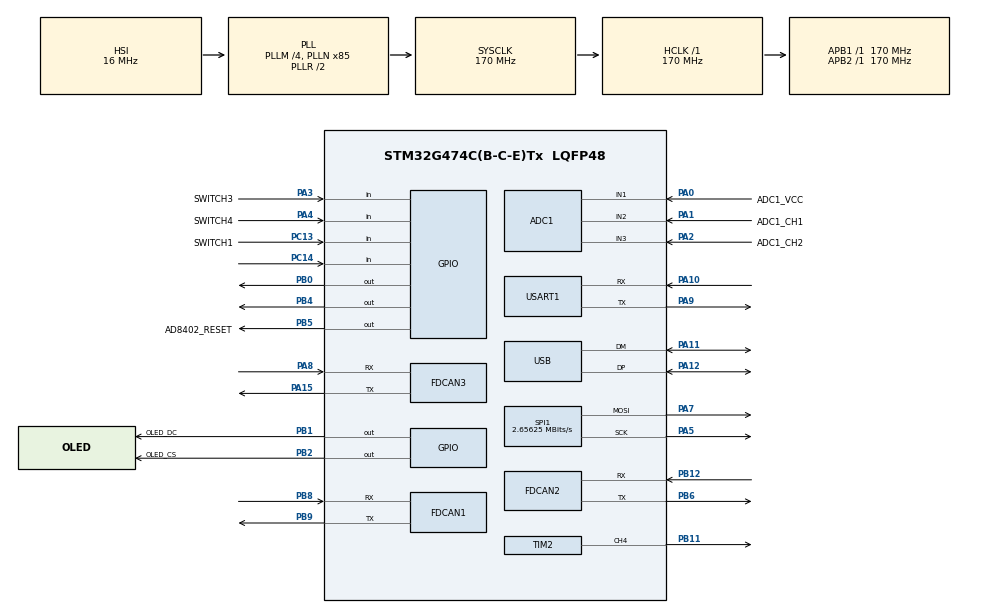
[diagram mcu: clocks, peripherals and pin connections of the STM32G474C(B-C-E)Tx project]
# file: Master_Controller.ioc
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ADC1.Channel-0\#ChannelRegularConversion=ADC_CHANNEL_VREFINT
ADC1.NbrOfConversionFlag=1
ADC1.OffsetNumber-0\#ChannelRegularConversion=ADC_OFFSET_NONE
ADC1.Rank-0\#ChannelRegularConversion=1
ADC1.SamplingTime-0\#ChannelRegularConversion=ADC_SAMPLETIME_2CYCLES_5
ADC1.master=1
Dma.Request0=USART1_RX
Dma.Request1=TIM2_CH4
Dma.TIM2_CH4.1.Direction=DMA_MEMORY_TO_PERIPH
Dma.TIM2_CH4.1.EventEnable=DISABLE
Dma.TIM2_CH4.1.Instance=DMA1_Channel2
Dma.TIM2_CH4.1.MemDataAlignment=DMA_MDATAALIGN_WORD
Dma.TIM2_CH4.1.MemInc=DMA_MINC_ENABLE
Dma.TIM2_CH4.1.Mode=DMA_CIRCULAR
Dma.TIM2_CH4.1.PeriphDataAlignment=DMA_PDATAALIGN_WORD
Dma.TIM2_CH4.1.PeriphInc=DMA_PINC_DISABLE
Dma.TIM2_CH4.1.Polarity=HAL_DMAMUX_REQ_GEN_RISING
Dma.TIM2_CH4.1.Priority=DMA_PRIORITY_LOW
Dma.TIM2_CH4.1.RequestNumber=1
Dma.TIM2_CH4.1.SignalID=NONE
Dma.TIM2_CH4.1.SyncEnable=DISABLE
Dma.TIM2_CH4.1.SyncPolarity=HAL_DMAMUX_SYNC_NO_EVENT
Dma.TIM2_CH4.1.SyncRequestNumber=1
Dma.TIM2_CH4.1.SyncSignalID=NONE
Dma.USART1_RX.0.Direction=DMA_PERIPH_TO_MEMORY
Dma.USART1_RX.0.EventEnable=DISABLE
Dma.USART1_RX.0.Instance=DMA1_Channel1
Dma.USART1_RX.0.MemDataAlignment=DMA_MDATAALIGN_BYTE
Dma.USART1_RX.0.MemInc=DMA_MINC_ENABLE
Dma.USART1_RX.0.Mode=DMA_NORMAL
Dma.USART1_RX.0.PeriphDataAlignment=DMA_PDATAALIGN_BYTE
Dma.USART1_RX.0.PeriphInc=DMA_PINC_DISABLE
Dma.USART1_RX.0.Polarity=HAL_DMAMUX_REQ_GEN_RISING
Dma.USART1_RX.0.Priority=DMA_PRIORITY_LOW
Dma.USART1_RX.0.RequestNumber=1
Dma.USART1_RX.0.SignalID=NONE
Dma.USART1_RX.0.SyncEnable=DISABLE
Dma.USART1_RX.0.SyncPolarity=HAL_DMAMUX_SYNC_NO_EVENT
Dma.USART1_RX.0.SyncRequestNumber=1
Dma.USART1_RX.0.SyncSignalID=NONE
FDCAN1.AutoRetransmission=ENABLE
FDCAN1.CalculateBaudRateNominal=1700000
FDCAN1.CalculateTimeBitNominal=588
FDCAN1.CalculateTimeQuantumNominal=58.82352941176471
FDCAN1.DataPrescaler=17
FDCAN1.DataTimeSeg1=6
FDCAN1.DataTimeSeg2=3
FDCAN1.ExtFiltersNbr=8
FDCAN1.NominalPrescaler=10
FDCAN1.NominalTimeSeg1=6
FDCAN1.NominalTimeSeg2=3
FDCAN1.ProtocolException=ENABLE
FDCAN1.StdFiltersNbr=8
FDCAN1.TransmitPause=ENABLE
FDCAN2.AutoRetransmission=ENABLE
FDCAN2.CalculateBaudRateNominal=1700000
FDCAN2.CalculateTimeBitNominal=588
FDCAN2.CalculateTimeQuantumNominal=58.82352941176471
FDCAN2.DataPrescaler=17
FDCAN2.DataSyncJumpWidth=1
FDCAN2.DataTimeSeg1=6
FDCAN2.DataTimeSeg2=3
FDCAN2.ExtFiltersNbr=8
FDCAN2.NominalPrescaler=10
FDCAN2.NominalTimeSeg1=6
FDCAN2.NominalTimeSeg2=3
FDCAN2.ProtocolException=ENABLE
FDCAN2.StdFiltersNbr=8
FDCAN2.TransmitPause=ENABLE
FDCAN3.CalculateBaudRateNominal=3541666
FDCAN3.CalculateTimeBitNominal=282
FDCAN3.CalculateTimeQuantumNominal=94.11764705882354
FREERTOS.Tasks01=defaultTask,24,256,StartDefaultTask,Default,NULL,Dynamic,NULL,NULL;RGB,9,512,Task_RGB,As weak,NULL,Dynamic,NULL,NULL;Communite,49,1024,Task_Communite,As weak,NULL,Dynamic,NULL,NULL;Main_Control,41,2048,Task_Main_Control,As weak,NULL,Dynamic,NULL,NULL;Error_Detect,16,256,Task_Error_Detect,As weak,NULL,Dynamic,NULL,NULL;OLED,8,2048,Task_OLED_Display,As weak,NULL,Dynamic,NULL,NULL
FREERTOS.configTOTAL_HEAP_SIZE=32767
Mcu.Family=STM32G4
Mcu.Name=STM32G474C(B-C-E)Tx
Mcu.Package=LQFP48
NVIC.DMA1_Channel1_IRQn=true\:5\:0\:false\:false\:true\:true\:false\:true\:true
NVIC.DMA1_Channel2_IRQn=true\:5\:0\:false\:false\:true\:true\:false\:true\:true
NVIC.FDCAN1_IT0_IRQn=true\:5\:0\:false\:false\:true\:true\:true\:true\:true
NVIC.FDCAN2_IT0_IRQn=true\:5\:0\:false\:false\:true\:true\:true\:true\:true
NVIC.PriorityGroup=NVIC_PRIORITYGROUP_4
NVIC.TIM1_TRG_COM_TIM17_IRQn=true\:15\:0\:false\:false\:true\:false\:false\:true\:true
NVIC.TIM1_UP_TIM16_IRQn=true\:5\:0\:false\:false\:true\:true\:true\:true\:true
NVIC.TIM2_IRQn=true\:5\:0\:false\:false\:true\:true\:true\:true\:true
NVIC.TimeBase=TIM1_TRG_COM_TIM17_IRQn
NVIC.TimeBaseIP=TIM17
PA0.GPIO_Label=ADC1_VCC
PA0.Mode=IN1-Single-Ended
PA0.Signal=ADC1_IN1
PA1.GPIO_Label=ADC1_CH1
PA1.Mode=IN2-Single-Ended
PA1.Signal=ADC1_IN2
PA10.Mode=Asynchronous
PA10.Signal=USART1_RX
PA11.Mode=Device
PA11.Signal=USB_DM
PA12.Mode=Device
PA12.Signal=USB_DP
PA13.Mode=Serial_Wire
PA13.Signal=SYS_JTMS-SWDIO
PA14.Mode=Serial_Wire
PA14.Signal=SYS_JTCK-SWCLK
PA15.Mode=FDCAN_Activate
PA15.Signal=FDCAN3_TX
PA2.GPIO_Label=ADC1_CH2
PA2.Mode=IN3-Single-Ended
PA2.Signal=ADC1_IN3
PA3.GPIO_Label=SWITCH3
PA3.Signal=GPIO_Input
PA4.GPIO_Label=SWITCH4
PA4.Signal=GPIO_Input
PA5.Mode=TX_Only_Simplex_Unidirect_Master
PA5.Signal=SPI1_SCK
PA7.Mode=TX_Only_Simplex_Unidirect_Master
PA7.Signal=SPI1_MOSI
PA8.Mode=FDCAN_Activate
PA8.Signal=FDCAN3_RX
PA9.Mode=Asynchronous
PA9.Signal=USART1_TX
PB0.GPIO_PuPd=GPIO_PULLUP
PB0.GPIO_Speed=GPIO_SPEED_FREQ_HIGH
PB0.Signal=GPIO_Output
PB1.GPIO_Label=OLED_DC
PB1.GPIO_PuPd=GPIO_PULLUP
PB1.GPIO_Speed=GPIO_SPEED_FREQ_HIGH
PB1.Signal=GPIO_Output
PB11.Signal=S_TIM2_CH4
PB12.Mode=FDCAN_Activate
PB12.Signal=FDCAN2_RX
PB2.GPIO_Label=OLED_CS
PB2.GPIO_PuPd=GPIO_PULLUP
PB2.GPIO_Speed=GPIO_SPEED_FREQ_HIGH
PB2.Signal=GPIO_Output
PB4.Signal=GPIO_Output
PB5.GPIO_Label=AD8402_RESET
PB5.Signal=GPIO_Output
PB6.Mode=FDCAN_Activate
PB6.Signal=FDCAN2_TX
PB8-BOOT0.Mode=FDCAN_Activate
PB8-BOOT0.Signal=FDCAN1_RX
PB9.Mode=FDCAN_Activate
PB9.Signal=FDCAN1_TX
PC13.GPIO_Label=SWITCH1
PC13.Signal=GPIO_Input
PC14-OSC32_IN.Signal=GPIO_Input
PF0-OSC_IN.Mode=HSE-External-Oscillator
PF0-OSC_IN.Signal=RCC_OSC_IN
PF1-OSC_OUT.Mode=HSE-External-Oscillator
PF1-OSC_OUT.Signal=RCC_OSC_OUT
ProjectManager.HeapSize=0x200
ProjectManager.StackSize=0x400
ProjectManager.TargetToolchain=MDK-ARM V5.32
RCC.ADC12Freq_Value=170000000
RCC.ADC345Freq_Value=170000000
RCC.AHBFreq_Value=170000000
RCC.APB1Freq_Value=170000000
RCC.APB1TimFreq_Value=170000000
RCC.APB2Freq_Value=170000000
RCC.APB2TimFreq_Value=170000000
RCC.CK48CLockSelection=RCC_USBCLKSOURCE_HSI48
RCC.CortexFreq_Value=170000000
RCC.EXTERNAL_CLOCK_VALUE=12288000
RCC.HCLKFreq_Value=170000000
RCC.HSE_VALUE=12000000
RCC.HSI48_VALUE=48000000
RCC.HSI_VALUE=16000000
RCC.LSE_VALUE=32768
RCC.PLLM=RCC_PLLM_DIV4
RCC.PLLN=85
RCC.PLLQ=RCC_PLLQ_DIV6
RCC.SYSCLKFreq_VALUE=170000000
RCC.SYSCLKSource=RCC_SYSCLKSOURCE_PLLCLK
RCC.USBFreq_Value=48000000
RCC.VCOOutputFreq_Value=340000000
SH.S_TIM2_CH4.0=TIM2_CH4,PWM Generation4 CH4
SPI1.BaudRatePrescaler=SPI_BAUDRATEPRESCALER_64
SPI1.CalculateBaudRate=2.65625 MBits/s
SPI1.DataSize=SPI_DATASIZE_10BIT
SPI1.Direction=SPI_DIRECTION_2LINES
SPI1.Mode=SPI_MODE_MASTER
SPI1.VirtualType=VM_MASTER
TIM1.PeriodNoDither=1000
TIM1.Prescaler=170
TIM2.AutoReloadPreload=TIM_AUTORELOAD_PRELOAD_ENABLE
TIM2.Channel-PWM\ Generation4\ CH4=TIM_CHANNEL_4
TIM2.ClockDivision=TIM_CLOCKDIVISION_DIV1
TIM2.PeriodNoDither=200-1
TIM2.PulseNoDither_4=0
USART1.VirtualMode-Asynchronous=VM_ASYNC
VP_ADC1_Vref_Input.Mode=IN-Vrefint
VP_FREERTOS_VS_CMSIS_V2.Mode=CMSIS_V2
VP_SYS_VS_DBSignals.Mode=DisableDeadBatterySignals
VP_SYS_VS_tim17.Mode=TIM17
VP_SYS_V_VREFBUF.Mode=ExternalMode
VP_TIM1_VS_ClockSourceINT.Mode=Internal
VP_TIM2_VS_ClockSourceINT.Mode=Internal
board=custom

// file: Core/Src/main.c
/* USER CODE BEGIN Header */
/**
  ******************************************************************************
  * @file           : main.c
  * @brief          : Main program body
  ******************************************************************************
  * @attention
  *
  * Copyright (c) 2025 STMicroelectronics.
  * All rights reserved.
  *
  * This software is licensed under terms that can be found in the LICENSE file
  * in the root directory of this software component.
  * If no LICENSE file comes with this software, it is provided AS-IS.
  *
  ******************************************************************************
  */
/* USER CODE END Header */
#include "main.h"
#include "cmsis_os.h"
#include "adc.h"
#include "dma.h"
#include "fdcan.h"
#include "spi.h"
#include "tim.h"
#include "usart.h"
#include "usb.h"
#include "gpio.h"

/* USER CODE BEGIN Includes */
#include "DC_Arm_Control.h"
/* USER CODE END Includes */

void SystemClock_Config(void);
void MX_FREERTOS_Init(void);

int main(void)
{

  /* MCU Configuration--------------------------------------------------------*/

  /* Reset of all peripherals, Initializes the Flash interface and the Systick. */
  HAL_Init();

  /* Configure the system clock */
  SystemClock_Config();

  /* Initialize all configured peripherals */
  MX_GPIO_Init();
  MX_DMA_Init();
  MX_FDCAN1_Init();
  MX_ADC1_Init();
  MX_TIM1_Init();
  MX_USART1_UART_Init();
  MX_FDCAN2_Init();
  MX_FDCAN3_Init();
  MX_TIM2_Init();
  MX_USB_PCD_Init();
  MX_SPI1_Init();

  /* Init scheduler */
  osKernelInitialize();

  /* Call init function for freertos objects (in cmsis_os2.c) */
  MX_FREERTOS_Init();

  /* Start scheduler */
  osKernelStart();

  /* We should never get here as control is now taken by the scheduler */

  /* Infinite loop */
  while (1)
  {

  }
}

void SystemClock_Config(void)
{
  RCC_OscInitTypeDef RCC_OscInitStruct = {0};
  RCC_ClkInitTypeDef RCC_ClkInitStruct = {0};

  /** Configure the main internal regulator output voltage
  */
  HAL_PWREx_ControlVoltageScaling(PWR_REGULATOR_VOLTAGE_SCALE1_BOOST);

  /** Initializes the RCC Oscillators according to the specified parameters
  * in the RCC_OscInitTypeDef structure.
  */
  RCC_OscInitStruct.OscillatorType = RCC_OSCILLATORTYPE_HSI|RCC_OSCILLATORTYPE_HSI48;
  RCC_OscInitStruct.HSIState = RCC_HSI_ON;
  RCC_OscInitStruct.HSICalibrationValue = RCC_HSICALIBRATION_DEFAULT;
  RCC_OscInitStruct.HSI48State = RCC_HSI48_ON;
  RCC_OscInitStruct.PLL.PLLState = RCC_PLL_ON;
  RCC_OscInitStruct.PLL.PLLSource = RCC_PLLSOURCE_HSI;
  RCC_OscInitStruct.PLL.PLLM = RCC_PLLM_DIV4;
  RCC_OscInitStruct.PLL.PLLN = 85;
  RCC_OscInitStruct.PLL.PLLP = RCC_PLLP_DIV2;
  RCC_OscInitStruct.PLL.PLLQ = RCC_PLLQ_DIV6;
  RCC_OscInitStruct.PLL.PLLR = RCC_PLLR_DIV2;
  if (HAL_RCC_OscConfig(&RCC_OscInitStruct) != HAL_OK)
  {
    Error_Handler();
  }

  /** Initializes the CPU, AHB and APB buses clocks
  */
  RCC_ClkInitStruct.ClockType = RCC_CLOCKTYPE_HCLK|RCC_CLOCKTYPE_SYSCLK
                              |RCC_CLOCKTYPE_PCLK1|RCC_CLOCKTYPE_PCLK2;
  RCC_ClkInitStruct.SYSCLKSource = RCC_SYSCLKSOURCE_PLLCLK;
  RCC_ClkInitStruct.AHBCLKDivider = RCC_SYSCLK_DIV1;
  RCC_ClkInitStruct.APB1CLKDivider = RCC_HCLK_DIV1;
  RCC_ClkInitStruct.APB2CLKDivider = RCC_HCLK_DIV1;

  if (HAL_RCC_ClockConfig(&RCC_ClkInitStruct, FLASH_LATENCY_4) != HAL_OK)
  {
    Error_Handler();
  }
}

void HAL_TIM_PeriodElapsedCallback(TIM_HandleTypeDef *htim)
{
  /* USER CODE BEGIN Callback 0 */
  if(htim->Instance == TIM1)
  {

  }
	else if(htim->Instance == TIM2)
	{

	}
  /* USER CODE END Callback 0 */
  if (htim->Instance == TIM17)
  {
    HAL_IncTick();
  }
}

void Error_Handler(void)
{
  __disable_irq();
  while (1)
  {
  }
}

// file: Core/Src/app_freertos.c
/* USER CODE BEGIN Header */
/**
  ******************************************************************************
  * File Name          : app_freertos.c
  * Description        : Code for freertos applications
  ******************************************************************************
  * @attention
  *
  * Copyright (c) 2025 STMicroelectronics.
  * All rights reserved.
  *
  * This software is licensed under terms that can be found in the LICENSE file
  * in the root directory of this software component.
  * If no LICENSE file comes with this software, it is provided AS-IS.
  *
  ******************************************************************************
  */
/* USER CODE END Header */

#include "FreeRTOS.h"
#include "task.h"
#include "main.h"
#include "cmsis_os.h"

/* Definitions for defaultTask */
osThreadId_t defaultTaskHandle;
const osThreadAttr_t defaultTask_attributes = {
  .name = "defaultTask",
  .priority = (osPriority_t) osPriorityNormal,
  .stack_size = 256 * 4
};
/* Definitions for RGB */
osThreadId_t RGBHandle;
const osThreadAttr_t RGB_attributes = {
  .name = "RGB",
  .priority = (osPriority_t) osPriorityLow1,
  .stack_size = 512 * 4
};
/* Definitions for Communite */
osThreadId_t CommuniteHandle;
const osThreadAttr_t Communite_attributes = {
  .name = "Communite",
  .priority = (osPriority_t) osPriorityRealtime1,
  .stack_size = 1024 * 4
};
/* Definitions for Main_Control */
osThreadId_t Main_ControlHandle;
const osThreadAttr_t Main_Control_attributes = {
  .name = "Main_Control",
  .priority = (osPriority_t) osPriorityHigh1,
  .stack_size = 2048 * 4
};
/* Definitions for Error_Detect */
osThreadId_t Error_DetectHandle;
const osThreadAttr_t Error_Detect_attributes = {
  .name = "Error_Detect",
  .priority = (osPriority_t) osPriorityBelowNormal,
  .stack_size = 256 * 4
};
/* Definitions for OLED */
osThreadId_t OLEDHandle;
const osThreadAttr_t OLED_attributes = {
  .name = "OLED",
  .priority = (osPriority_t) osPriorityLow,
  .stack_size = 2048 * 4
};

void StartDefaultTask(void *argument);
void Task_RGB(void *argument);
void Task_Communite(void *argument);
void Task_Main_Control(void *argument);
void Task_Error_Detect(void *argument);
void Task_OLED_Display(void *argument);

void MX_FREERTOS_Init(void); /* (MISRA C 2004 rule 8.1) */

void MX_FREERTOS_Init(void) {

  /* Create the thread(s) */
  /* creation of defaultTask */
  defaultTaskHandle = osThreadNew(StartDefaultTask, NULL, &defaultTask_attributes);

  /* creation of RGB */
  RGBHandle = osThreadNew(Task_RGB, NULL, &RGB_attributes);

  /* creation of Communite */
  CommuniteHandle = osThreadNew(Task_Communite, NULL, &Communite_attributes);

  /* creation of Main_Control */
  Main_ControlHandle = osThreadNew(Task_Main_Control, NULL, &Main_Control_attributes);

  /* creation of Error_Detect */
  Error_DetectHandle = osThreadNew(Task_Error_Detect, NULL, &Error_Detect_attributes);

  /* creation of OLED */
  OLEDHandle = osThreadNew(Task_OLED_Display, NULL, &OLED_attributes);

}

void StartDefaultTask(void *argument)
{
  for(;;)
  {
    osDelay(1);
  }
}

__weak void Task_RGB(void *argument)
{
  for(;;)
  {
    osDelay(1);
  }
}

__weak void Task_Communite(void *argument)
{
  for(;;)
  {
    osDelay(1);
  }
}

__weak void Task_Main_Control(void *argument)
{
  for(;;)
  {
    osDelay(1);
  }
}

__weak void Task_Error_Detect(void *argument)
{
  for(;;)
  {
    osDelay(1);
  }
}

__weak void Task_OLED_Display(void *argument)
{
  for(;;)
  {
    osDelay(1);
  }
}
